# TC37X register map
File version: 1.0.0
CPU: CM4 r0p1, little endian, MPU, FPU, VTOR, 3 interrupt priority bits
Registers are 16-bit, read-write, reset 0x0 unless marked. A register's access mark holds for its fields unless they carry their own. Offsets are from the block's base; [hi:lo] are bit positions; {n}, {i} and the like mark numbered series.

## EDSADC — ce_edsadc
Base 0xF0024000
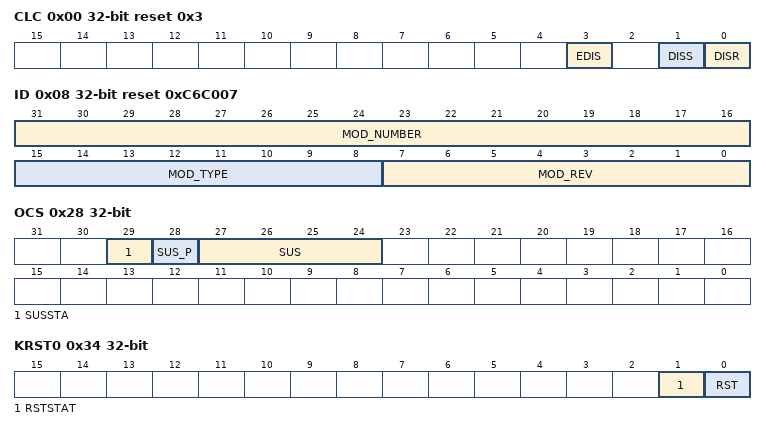
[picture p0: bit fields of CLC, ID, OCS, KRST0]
0x00 CLC 32-bit reset 0x3 — Clock Control Register
  [3] EDIS — Sleep Mode Enable Control - EDIS
  [1] DISS ro — Module Disable Status Bit - DISS
  [0] DISR — Module Disable Request Bit - DISR
0x08 ID 32-bit ro reset 0xC6C007 — Module Identification Register
  [31:16] MOD_NUMBER — Module Number - MOD_NUMBER
  [15:8] MOD_TYPE — Module Type - MOD_TYPE
  [7:0] MOD_REV — Module Revision - MOD_REV
0x28 OCS 32-bit — OCDS Control and Status Register
  [29] SUSSTA ro — Suspend State - SUSSTA
  [28] SUS_P wo — SUS Write Protection - SUS_P
  [27:24] SUS — OCDS Suspend Control - SUS
0x2C KRSTCLR 32-bit wo — Kernel Reset Status Clear Register
  [0] CLR — Kernel Reset Status Clear - CLR
0x30 KRST1 32-bit — Kernel Reset Register 1
  [0] RST — Kernel Reset - RST
0x34 KRST0 32-bit — Kernel Reset Register 0
  [1] RSTSTAT ro — Kernel Reset Status - RSTSTAT
  [0] RST — Kernel Reset - RST
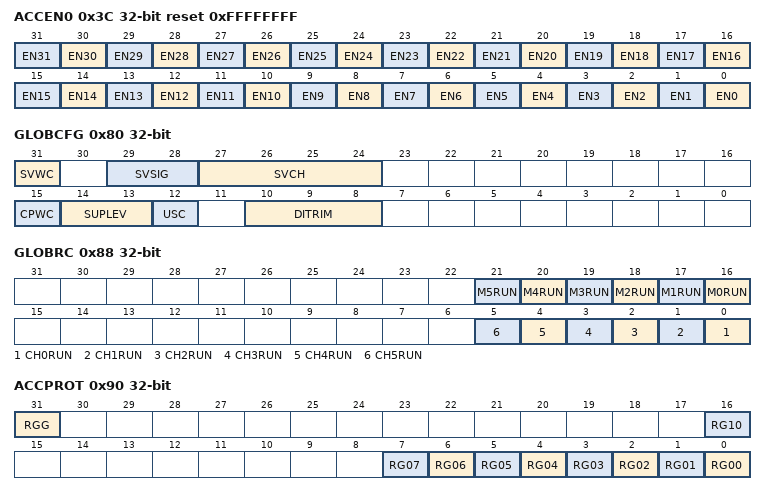
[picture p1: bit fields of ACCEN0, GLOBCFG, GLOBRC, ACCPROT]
0x3C ACCEN0 32-bit reset 0xFFFFFFFF — Access Enable Register 0
  [n] EN{n} (n=0..31) — Access Enable for Master TAG ID {n} - EN{n}
0x80 GLOBCFG 32-bit — Global Configuration Register
  [31] SVWC wo — Write Control for Supervision Parameters
  [29:28] SVSIG — Supervision Signal Select
  [27:24] SVCH — Supervision Channel Select
  [15] CPWC wo — Write Control for Clock Parameters - CPWC
  [14:13] SUPLEV — Supply Voltage Level
  [12] USC — Unsynchronized Clock Generation - USC
  [10:8] DITRIM — Trimming Value for the Dithering Function - DITRIM
0x88 GLOBRC 32-bit — Global Run Control Register
  [n+16] M{n}RUN (n=0..5) — Modulator {n} Run Control - M{n}RUN
  [n] CH{n}RUN (n=0..5) — Channel {n} Run Control - CH{n}RUN
0x90 ACCPROT 32-bit — Access Protection Register
  [31] RGG — Register Group Global - RGG
  [16] RG10 — Register Group 10 - RG10
  [n] RG{n:02} (n=0..7) — Register Group {n} - RG{n:02}
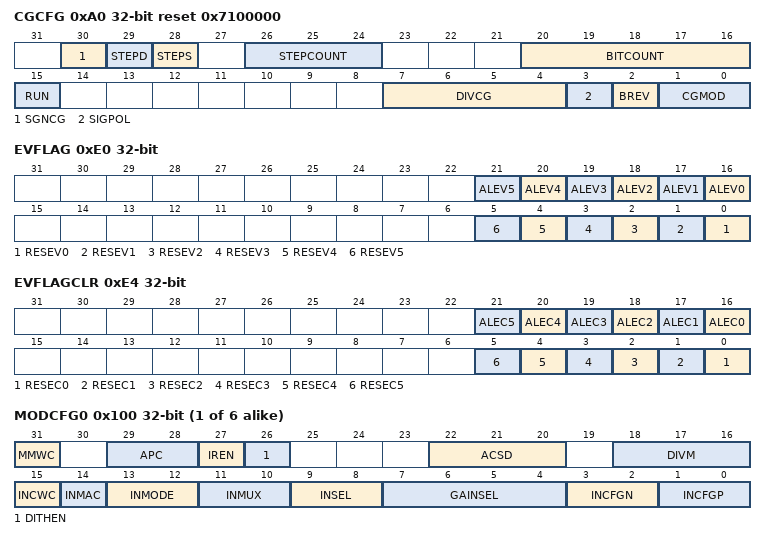
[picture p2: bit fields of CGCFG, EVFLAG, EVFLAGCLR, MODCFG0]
0xA0 CGCFG 32-bit reset 0x7100000 — Carrier Generator Configuration Register
  [30] SGNCG ro — Sign Signal from Carrier Generator - SGNCG
  [29] STEPD ro — Step Counter Direction - STEPD
  [28] STEPS ro — Step Counter Sign - STEPS
  [26:24] STEPCOUNT ro — Step Counter - STEPCOUNT
  [20:16] BITCOUNT ro — Bit Counter - BITCOUNT
  [15] RUN ro — Run Indicator - RUN
  [7:4] DIVCG — Divider Factor for the PWM Pattern Signal Generator - DIVCG
  [3] SIGPOL — Signal Polarity - SIGPOL
  [2] BREV — Bit-Reverse PWM Generation - BREV
  [1:0] CGMOD — Carrier Generator Operating Mode - CGMOD
0xE0 EVFLAG 32-bit — Event Flag Register
  [n+16] ALEV{n} (n=0..5) — Alarm Event - ALEV{n}
  [n] RESEV{n} (n=0..5) — Result Event - RESEV{n}
0xE4 EVFLAGCLR 32-bit wo — Event Flag Clear Register
  [n+16] ALEC{n} (n=0..5) — Alarm Event Clear - ALEC{n}
  [n] RESEC{n} (n=0..5) — Result Event Clear - RESEC{n}
{0x100+0x100*i} MODCFG{i} 32-bit (i=0..5) — Modulator Configuration Register {i}
  [31] MMWC wo — Write Control for Modulator Mode Settings - MMWC
  [29:28] APC — Automatic Power Control - APC
  [27] IREN — Integrator Reset Enable - IREN
  [26] DITHEN — Dithering Function Enable - DITHEN
  [22:20] ACSD — Analog Clock Synchronization Delay - ACSD
  [18:16] DIVM — Modulator Clock Period - DIVM
  [15] INCWC wo — Write Control for Input Parameters - INCWC
  [14] INMAC — Input Multiplexer Action Control - INMAC
  [13:12] INMODE — Input Multiplexer Control Mode - INMODE
  [11:10] INMUX ro — Input Multiplexer Setting - INMUX
  [9:8] INSEL — Input Pin Selection - INSEL
  [7:4] GAINSEL — Gain Select of Analog Input Path - GAINSEL
  [3:2] INCFGN — Configuration of Negative Input Line - INCFGN
  [1:0] INCFGP — Configuration of Positive Input Line - INCFGP
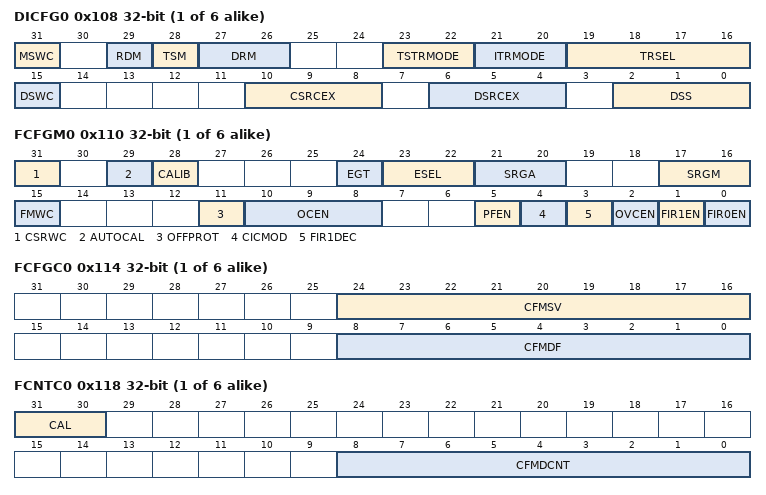
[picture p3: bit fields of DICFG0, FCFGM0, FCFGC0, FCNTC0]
{0x108+0x100*i} DICFG{i} 32-bit (i=0..5) — Demodulator Input Config. Register {i}
  [31] MSWC wo — Write Control for Mode Settings - MSWC
  [29] RDM — Result Display Mode - RDM
  [28] TSM — Time-Stamp Mode - TSM
  [27:26] DRM — Data Read Mode - DRM
  [23:22] TSTRMODE — Timestamp Trigger Mode - TSTRMODE
  [21:20] ITRMODE — Integrator Trigger Mode - ITRMODE
  [19:16] TRSEL — Trigger Select - TRSEL
  [15] DSWC wo — Write Control for Data Stream Selection - DSWC
  [10:8] CSRCEX — Clock Source for External Modulator - CSRCEX
  [6:4] DSRCEX — Data Source for External Modulator - DSRCEX
  [2:0] DSS — Data Stream Select - DSS
{0x110+0x100*i} FCFGM{i} 32-bit (i=0..5) — Filter Configuration Register {i}, Main
  [31] CSRWC wo — Write Control for Calibration and Service Request Modes - CSRWC
  [29] AUTOCAL — Automatic Calibration Control - AUTOCAL
  [28] CALIB wo — Calibration Trigger - CALIB
  [24] EGT — Event Gating
  [23:22] ESEL — Event Select - ESEL
  [21:20] SRGA — Service Request Generation for Alternate Service Request - SRGA
  [17:16] SRGM — Service Request Generation for Main Service Request - SRGM
  [15] FMWC wo — Write Control for Filter Modes - FMWC
  [11] OFFPROT — Offset Protection - OFFPROT
  [10:8] OCEN — Offset Compensation Filter Enable - OCEN
  [5] PFEN — Prefilter Enable - PFEN
  [4] CICMOD — CIC Filter Mode - CICMOD
  [3] FIR1DEC — FIR1 Filter Decimation Rate - FIR1DEC
  [2] OVCEN — Overshoot Compensation Enable
  [1] FIR1EN — FIR1 Filter Enable - FIR1EN
  [0] FIR0EN — FIR0 Filter Enable - FIR0EN
{0x114+0x100*i} FCFGC{i} 32-bit (i=0..5) — Filter Configuration Register {i}, CIC Filter
  [24:16] CFMSV — CIC Filter Start Value - CFMSV
  [8:0] CFMDF — CIC Filter Decimation Factor - CFMDF
{0x118+0x100*i} FCNTC{i} 32-bit ro (i=0..5) — Filter Counter Register {i}, CIC Filter
  [31:30] CAL — Calibration Status Flag - CAL
  [8:0] CFMDCNT — CIC Filter Decimation Counter - CFMDCNT
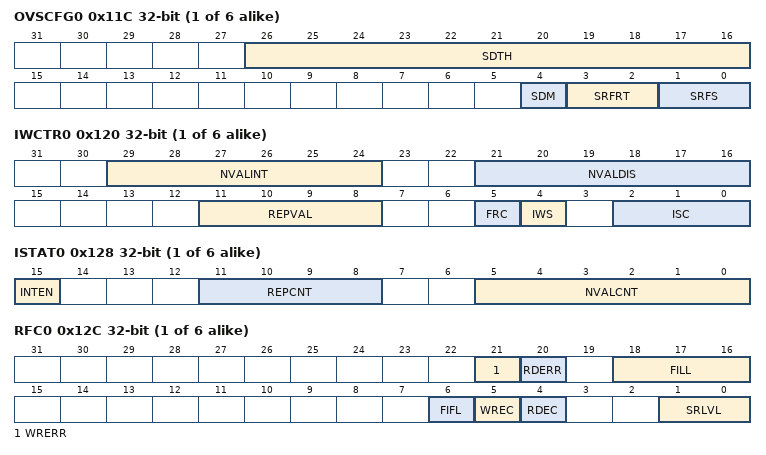
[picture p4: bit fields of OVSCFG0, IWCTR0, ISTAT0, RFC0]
{0x11C+0x100*i} OVSCFG{i} 32-bit (i=0..5) — Overshoot Compensation Cfg. Register {i}
  [26:16] SDTH — Step Detection Threshold
  [4] SDM — Step Detection Mode
  [3:2] SRFRT — Slew Rate Filter Run Time
  [1:0] SRFS — Slew Rate Filter Strength
{0x120+0x100*i} IWCTR{i} 32-bit (i=0..5) — Integration Window Control Register {i}
  [29:24] NVALINT — Number of Values to be Accumulated - NVALINT
  [21:16] NVALDIS — Number of Values Discarded - NVALDIS
  [11:8] REPVAL — Number of Integration Cycles - REPVAL
  [5] FRC — Filter Chain Restart Control
  [4] IWS — Integration Window Size - IWS
  [2:0] ISC — Integrator Shift Control - ISC
{0x124+0x100*i} IIVAL{i} 32-bit ro (i=0..5) — Intermediate Integration Value
  [25:0] IVAL — Result of most recent accumulation - IVAL
{0x128+0x100*i} ISTAT{i} 32-bit ro (i=0..5) — Integrator Status Register {i}
  [15] INTEN — Integration Enable - INTEN
  [11:8] REPCNT — Integration Cycle Counter - REPCNT
  [5:0] NVALCNT — Number of Values Counted - NVALCNT
{0x12C+0x100*i} RFC{i} 32-bit (i=0..5) — Result FIFO Control Register {i}
  [21] WRERR ro — Write Error Flag
  [20] RDERR ro — Read Error Flag
  [18:16] FILL ro — FIFO Fill Level
  [6] FIFL wo — FIFO Flush
  [5] WREC wo — Write Error Flag Clear
  [4] RDEC wo — Read Error Flag Clear
  [1:0] SRLVL — Service Request FIFO Level
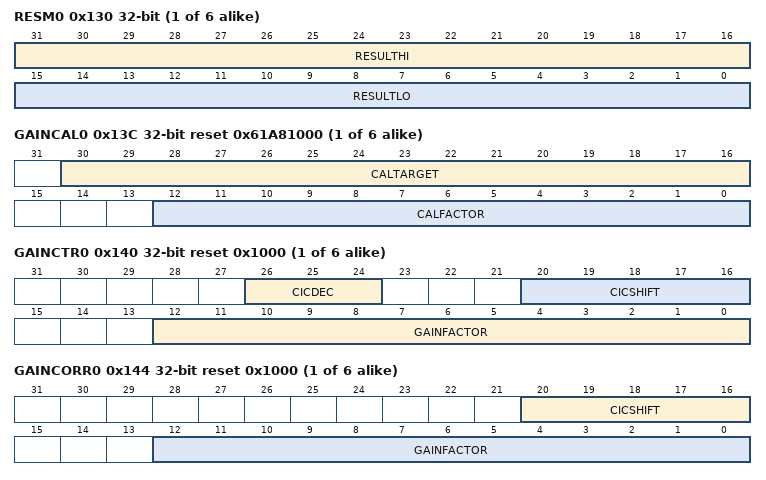
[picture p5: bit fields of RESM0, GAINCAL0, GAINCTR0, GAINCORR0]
{0x130+0x100*i} RESM{i} 32-bit ro (i=0..5) — Result Register {i} Main
  [31:16] RESULTHI — Result Value Higher Part - RESULTHI
  [15:0] RESULTLO — Result Value Lower Part - RESULTLO
{0x138+0x100*i} OFFCOMP{i} 32-bit (i=0..5) — Offset Compensation Register {i}
  [15:0] OFFSET — Offset Value - OFFSET
{0x13C+0x100*i} GAINCAL{i} 32-bit reset 0x61A81000 (i=0..5) — Gain Calibration Register {i}
  [30:16] CALTARGET — Target Value for Calibrated Fullscale - CALTARGET
  [12:0] CALFACTOR — Multiplication Factor for Gain Calibration - CALFACTOR
{0x140+0x100*i} GAINCTR{i} 32-bit reset 0x1000 (i=0..5) — Gain Control Register {i}
  [26:24] CICDEC — Decimation Rate of the CIC Filter During Calibration - CICDEC
  [20:16] CICSHIFT — Position of the CIC Filter Output Shifter During Calibration - CICSHIFT
  [12:0] GAINFACTOR — Multiplication Factor for Gain Correction During Calibration - GAINFACTOR
{0x144+0x100*i} GAINCORR{i} 32-bit reset 0x1000 (i=0..5) — Gain Correction Register {i}
  [20:16] CICSHIFT — Position of the CIC Filter Output Shifter
  [12:0] GAINFACTOR — Multiplication Factor for Gain Correction - GAINFACTOR
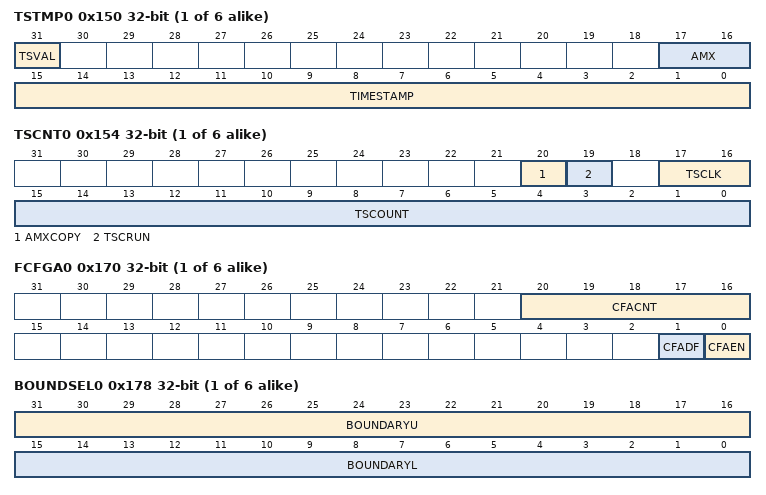
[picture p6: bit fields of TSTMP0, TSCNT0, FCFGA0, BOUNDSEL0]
{0x150+0x100*i} TSTMP{i} 32-bit ro (i=0..5) — Time-Stamp Register {i}
  [31] TSVAL — Timestamp Valid - TSVAL
  [17:16] AMX — Analog Multiplexer Setting - AMX
  [15:0] TIMESTAMP — The Most Recent Captured Timestamp Value - TIMESTAMP
{0x154+0x100*i} TSCNT{i} 32-bit (i=0..5) — Time-Stamp Counter {i}
  [20] AMXCOPY — Analog MUX Setting Copy Enable - AMXCOPY
  [19] TSCRUN — Timestamp Counter Run Control - TSCRUN
  [17:16] TSCLK — Timestamp Counter Clock Selection - TSCLK
  [15:0] TSCOUNT ro — Timestamp Counter Value - TSCOUNT
{0x170+0x100*i} FCFGA{i} 32-bit (i=0..5) — Auxiliary Filter Configuration Register {i}
  [20:16] CFACNT ro — CIC Filter (Auxiliary) Decimation Counter
  [1] CFADF — CIC Filter (Auxiliary) Decimation Factor
  [0] CFAEN — CIC Filter (Auxiliary) Enable
{0x178+0x100*i} BOUNDSEL{i} 32-bit (i=0..5) — Boundary Select Register {i}
  [31:16] BOUNDARYU — Upper Boundary Value for Limit Checking - BOUNDARYU
  [15:0] BOUNDARYL — Lower Boundary Value for Limit Checking - BOUNDARYL
{0x180+0x100*i} RESA{i} 32-bit ro (i=0..5) — Result Register {i} Auxiliary
  [15:0] RESULT — Most Recent Result of Auxiliary Filter
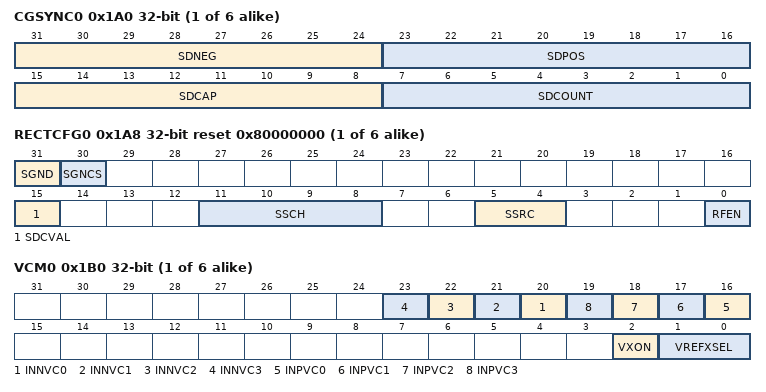
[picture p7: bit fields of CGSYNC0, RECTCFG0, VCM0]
{0x1A0+0x100*i} CGSYNC{i} 32-bit (i=0..5) — Carrier Generator Synchronization Reg. {i}
  [31:24] SDNEG — Sign Delay Value for Negative Halfwave - SDNEG
  [23:16] SDPOS — Sign Delay Value for Positive Halfwave - SDPOS
  [15:8] SDCAP ro — Sign Delay Capture Value - SDCAP
  [7:0] SDCOUNT ro — Sign Delay Counter - SDCOUNT
{0x1A8+0x100*i} RECTCFG{i} 32-bit reset 0x80000000 (i=0..5) — Rectification Configuration Register {i}
  [31] SGND ro — Sign Signal Delayed - SGND
  [30] SGNCS ro — Selected Carrier Sign Signal - SGNCS
  [15] SDCVAL ro — Valid Flag - SDCVAL
  [11:8] SSCH — Sign Source Channel
  [5:4] SSRC — Sign Source
  [0] RFEN — Rectification Enable - RFEN
{0x1B0+0x100*i} VCM{i} 32-bit (i=0..5) — Common Mode Voltage Register {i}
  [n+20] INNVC{n} (n=0..3) — Voltage Control of Negative Inputs {n} of CH{i}
  [n+16] INPVC{n} (n=0..3) — Voltage Control of Positive Inputs {n} of CH{i}
  [2] VXON — Fractional Reference Voltage Enable - VXON
  [1:0] VREFXSEL — Fractional Reference Voltage Selection - VREFXSEL
